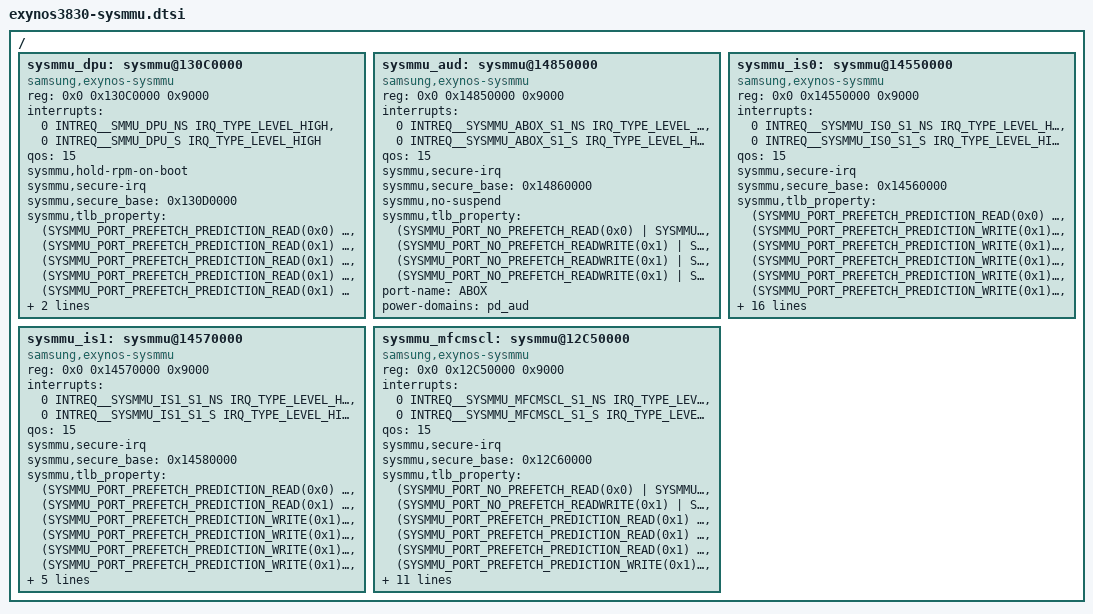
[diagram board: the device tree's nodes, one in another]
/*
 * SAMSUNG EXYNOS3830 SoC device tree source
 *
 * Copyright (c) 2019 Samsung Electronics Co., Ltd.
 *		http://www.samsung.com
 *
 * SAMSUNG EXYNOS3830 SoC device nodes are listed in this file.
 * EXYNOS3830 based board files can include this file and provide
 * values for board specfic bindings.
 *
 * This program is free software; you can redistribute it and/or modify
 * it under the terms of the GNU General Public License version 2 as
 * published by the Free Software Foundation.
 */

#include <dt-bindings/interrupt-controller/arm-gic.h>
#include <dt-bindings/sysmmu/sysmmu.h>

/ {
	sysmmu_dpu: sysmmu@130C0000 {
		compatible = "samsung,exynos-sysmmu";
		reg = <0x0 0x130C0000 0x9000>;
		interrupts = <0 INTREQ__SMMU_DPU_NS IRQ_TYPE_LEVEL_HIGH>,
			     <0 INTREQ__SMMU_DPU_S  IRQ_TYPE_LEVEL_HIGH>;
		qos = <15>;

		sysmmu,hold-rpm-on-boot;
		sysmmu,secure-irq;
		sysmmu,secure_base = <0x130D0000>;
		sysmmu,tlb_property =
			<(SYSMMU_PORT_PREFETCH_PREDICTION_READ(0x0) | SYSMMU_BL1) SYSMMU_NOID>,
			<(SYSMMU_PORT_PREFETCH_PREDICTION_READ(0x1) | SYSMMU_BL1) SYSMMU_ID_MASK(0x2, 0xF)>,
			<(SYSMMU_PORT_PREFETCH_PREDICTION_READ(0x1) | SYSMMU_BL1) SYSMMU_ID_MASK(0x4, 0xF)>,
			<(SYSMMU_PORT_PREFETCH_PREDICTION_READ(0x1) | SYSMMU_BL1) SYSMMU_ID_MASK(0x6, 0xF)>,
			<(SYSMMU_PORT_PREFETCH_PREDICTION_READ(0x1) | SYSMMU_BL1) SYSMMU_ID_MASK(0x8, 0xF)>;
		port-name = "DPU";
		#iommu-cells = <0>;
		power-domains = <&pd_dpu>;
	};

	sysmmu_aud: sysmmu@14850000 {
		compatible = "samsung,exynos-sysmmu";
		reg = <0x0 0x14850000 0x9000>;
		interrupts = <0 INTREQ__SYSMMU_ABOX_S1_NS IRQ_TYPE_LEVEL_HIGH>,
			     <0 INTREQ__SYSMMU_ABOX_S1_S  IRQ_TYPE_LEVEL_HIGH>;
		qos = <15>;

		sysmmu,secure-irq;
		sysmmu,secure_base = <0x14860000>;
		sysmmu,no-suspend;
		sysmmu,tlb_property =
			<(SYSMMU_PORT_NO_PREFETCH_READ(0x0)      | SYSMMU_BL1) SYSMMU_NOID>,
			<(SYSMMU_PORT_NO_PREFETCH_READWRITE(0x1) | SYSMMU_BL1) SYSMMU_ID_MASK(0x5, 0xF)>,
			<(SYSMMU_PORT_NO_PREFETCH_READWRITE(0x1) | SYSMMU_BL1) SYSMMU_ID_MASK(0x0, 0x3)>,
			<(SYSMMU_PORT_NO_PREFETCH_READWRITE(0x1) | SYSMMU_BL1) SYSMMU_ID_MASK(0x3, 0x3)>;
		port-name = "ABOX";
		#iommu-cells = <0>;
		power-domains = <&pd_aud>;
	};

	sysmmu_is0: sysmmu@14550000 {
		compatible = "samsung,exynos-sysmmu";
		reg = <0x0 0x14550000 0x9000>;
		interrupts = <0 INTREQ__SYSMMU_IS0_S1_NS IRQ_TYPE_LEVEL_HIGH>,
			     <0 INTREQ__SYSMMU_IS0_S1_S  IRQ_TYPE_LEVEL_HIGH>;
		qos = <15>;

		sysmmu,secure-irq;
		sysmmu,secure_base = <0x14560000>;
		sysmmu,tlb_property =
			<(SYSMMU_PORT_PREFETCH_PREDICTION_READ(0x0)  | SYSMMU_BL1) SYSMMU_NOID>,
			<(SYSMMU_PORT_PREFETCH_PREDICTION_WRITE(0x1) | SYSMMU_BL1) SYSMMU_ID_MASK(0x2,  0x1F)>,
			<(SYSMMU_PORT_PREFETCH_PREDICTION_WRITE(0x1) | SYSMMU_BL1) SYSMMU_ID_MASK(0x4,  0x1F)>,
			<(SYSMMU_PORT_PREFETCH_PREDICTION_WRITE(0x1) | SYSMMU_BL1) SYSMMU_ID_MASK(0x6,  0x1F)>,
			<(SYSMMU_PORT_PREFETCH_PREDICTION_WRITE(0x1) | SYSMMU_BL1) SYSMMU_ID_MASK(0x8,  0x1F)>,
			<(SYSMMU_PORT_PREFETCH_PREDICTION_WRITE(0x1) | SYSMMU_BL1) SYSMMU_ID_MASK(0xA,  0x1F)>,
			<(SYSMMU_PORT_PREFETCH_PREDICTION_WRITE(0x1) | SYSMMU_BL1) SYSMMU_ID_MASK(0xC,  0x1F)>,
			<(SYSMMU_PORT_PREFETCH_PREDICTION_WRITE(0x1) | SYSMMU_BL1) SYSMMU_ID_MASK(0xE,  0x1F)>,
			<(SYSMMU_PORT_PREFETCH_PREDICTION_READ(0x1)  | SYSMMU_BL1) SYSMMU_ID_MASK(0x1,  0x1F)>,
			<(SYSMMU_PORT_PREFETCH_PREDICTION_READ(0x1)  | SYSMMU_BL1) SYSMMU_ID_MASK(0x11, 0x1F)>,
			<(SYSMMU_PORT_PREFETCH_PREDICTION_WRITE(0x1) | SYSMMU_BL1) SYSMMU_ID_MASK(0x1,  0x1F)>,
			<(SYSMMU_PORT_PREFETCH_PREDICTION_WRITE(0x1) | SYSMMU_BL1) SYSMMU_ID_MASK(0x3,  0x1F)>,
			<(SYSMMU_PORT_PREFETCH_PREDICTION_WRITE(0x1) | SYSMMU_BL1) SYSMMU_ID_MASK(0x5,  0x1F)>,
			<(SYSMMU_PORT_PREFETCH_PREDICTION_WRITE(0x1) | SYSMMU_BL1) SYSMMU_ID_MASK(0x7,  0x1F)>,
			<(SYSMMU_PORT_PREFETCH_PREDICTION_WRITE(0x1) | SYSMMU_BL1) SYSMMU_ID_MASK(0x9,  0x1F)>,
			<(SYSMMU_PORT_PREFETCH_PREDICTION_WRITE(0x1) | SYSMMU_BL1) SYSMMU_ID_MASK(0x11, 0x1F)>,
			<(SYSMMU_PORT_PREFETCH_PREDICTION_WRITE(0x1) | SYSMMU_BL1) SYSMMU_ID_MASK(0x13, 0x1F)>,
			<(SYSMMU_PORT_PREFETCH_PREDICTION_WRITE(0x1) | SYSMMU_BL1) SYSMMU_ID_MASK(0x15, 0x1F)>,
			<(SYSMMU_PORT_PREFETCH_PREDICTION_WRITE(0x1) | SYSMMU_BL1) SYSMMU_ID_MASK(0x17, 0x1F)>,
			<(SYSMMU_PORT_PREFETCH_PREDICTION_WRITE(0x1) | SYSMMU_BL1) SYSMMU_ID_MASK(0x19, 0x1F)>;
		port-name = "CSISX2, IPP";
		#iommu-cells = <0>;
		power-domains = <&pd_is>;
	};

	sysmmu_is1: sysmmu@14570000 {
		compatible = "samsung,exynos-sysmmu";
		reg = <0x0 0x14570000 0x9000>;
		interrupts = <0 INTREQ__SYSMMU_IS1_S1_NS IRQ_TYPE_LEVEL_HIGH>,
			     <0 INTREQ__SYSMMU_IS1_S1_S  IRQ_TYPE_LEVEL_HIGH>;
		qos = <15>;

		sysmmu,secure-irq;
		sysmmu,secure_base = <0x14580000>;
		sysmmu,tlb_property =
			<(SYSMMU_PORT_PREFETCH_PREDICTION_READ(0x0)  | SYSMMU_BL1) SYSMMU_NOID>,
			<(SYSMMU_PORT_PREFETCH_PREDICTION_READ(0x1)  | SYSMMU_BL1) SYSMMU_ID_MASK(0x4, 0x3F)>,
			<(SYSMMU_PORT_PREFETCH_PREDICTION_WRITE(0x1) | SYSMMU_BL1) SYSMMU_ID_MASK(0x4, 0x3F)>,
			<(SYSMMU_PORT_PREFETCH_PREDICTION_WRITE(0x1) | SYSMMU_BL1) SYSMMU_ID_MASK(0x1, 0x3F)>,
			<(SYSMMU_PORT_PREFETCH_PREDICTION_WRITE(0x1) | SYSMMU_BL1) SYSMMU_ID_MASK(0x5, 0x3F)>,
			<(SYSMMU_PORT_PREFETCH_PREDICTION_WRITE(0x1) | SYSMMU_BL1) SYSMMU_ID_MASK(0x9, 0x3F)>,
			<(SYSMMU_PORT_PREFETCH_PREDICTION_READWRITE(0x1) | SYSMMU_BL1) SYSMMU_ID_MASK(0x3, 0x3)>,
			<(SYSMMU_PORT_PREFETCH_PREDICTION_READ(0x1)  | SYSMMU_BL4) SYSMMU_ID_MASK(0x2, 0x3)>,
			<(SYSMMU_PORT_PREFETCH_PREDICTION_WRITE(0x1) | SYSMMU_BL1) SYSMMU_ID_MASK(0x2, 0x3)>;
		port-name = "ITP, MCSC, VRA, GDC";
		#iommu-cells = <0>;
		power-domains = <&pd_is>;
	};

	sysmmu_mfcmscl: sysmmu@12C50000 {
		compatible = "samsung,exynos-sysmmu";
		reg = <0x0 0x12C50000 0x9000>;
		interrupts = <0 INTREQ__SYSMMU_MFCMSCL_S1_NS IRQ_TYPE_LEVEL_HIGH>,
			     <0 INTREQ__SYSMMU_MFCMSCL_S1_S  IRQ_TYPE_LEVEL_HIGH>;
		qos = <15>;

		sysmmu,secure-irq;
		sysmmu,secure_base = <0x12C60000>;
		sysmmu,tlb_property =
			<(SYSMMU_PORT_NO_PREFETCH_READ(0x0)          | SYSMMU_BL8) SYSMMU_NOID>,
			<(SYSMMU_PORT_NO_PREFETCH_READWRITE(0x1)     | SYSMMU_BL2) SYSMMU_ID_MASK(0x1,  0x3F)>,
			<(SYSMMU_PORT_PREFETCH_PREDICTION_READ(0x1)  | SYSMMU_BL1) SYSMMU_ID_MASK(0x2,  0x3F)>,
			<(SYSMMU_PORT_PREFETCH_PREDICTION_READ(0x1)  | SYSMMU_BL1) SYSMMU_ID_MASK(0x6,  0x3F)>,
			<(SYSMMU_PORT_PREFETCH_PREDICTION_READ(0x1)  | SYSMMU_BL1) SYSMMU_ID_MASK(0xA,  0x3F)>,
			<(SYSMMU_PORT_PREFETCH_PREDICTION_WRITE(0x1) | SYSMMU_BL1) SYSMMU_ID_MASK(0x2,  0x3F)>,
			<(SYSMMU_PORT_PREFETCH_PREDICTION_WRITE(0x1) | SYSMMU_BL1) SYSMMU_ID_MASK(0x6,  0x3F)>,
			<(SYSMMU_PORT_PREFETCH_PREDICTION_WRITE(0x1) | SYSMMU_BL1) SYSMMU_ID_MASK(0xA,  0x3F)>,
			<(SYSMMU_PORT_PREFETCH_PREDICTION_READ(0x1)  | SYSMMU_BL1) SYSMMU_ID_MASK(0x3,  0x3F)>,
			<(SYSMMU_PORT_PREFETCH_PREDICTION_READ(0x1)  | SYSMMU_BL1) SYSMMU_ID_MASK(0x7,  0x3F)>,
			<(SYSMMU_PORT_PREFETCH_PREDICTION_READ(0x1)  | SYSMMU_BL1) SYSMMU_ID_MASK(0xB,  0x3F)>,
			<(SYSMMU_PORT_PREFETCH_PREDICTION_READ(0x1)  | SYSMMU_BL1) SYSMMU_ID_MASK(0xF,  0x3F)>,
			<(SYSMMU_PORT_PREFETCH_PREDICTION_WRITE(0x1) | SYSMMU_BL1) SYSMMU_ID_MASK(0x23, 0x3F)>,
			<(SYSMMU_PORT_PREFETCH_PREDICTION_WRITE(0x1) | SYSMMU_BL1) SYSMMU_ID_MASK(0x27, 0x3F)>,
			<(SYSMMU_PORT_PREFETCH_PREDICTION_WRITE(0x1) | SYSMMU_BL1) SYSMMU_ID_MASK(0x2B, 0x3F)>;
		port-name = "MFC, JPEG, MCSC, MSCL";
		#iommu-cells = <0>;
		power-domains = <&pd_mfcmscl>;
	};
};
